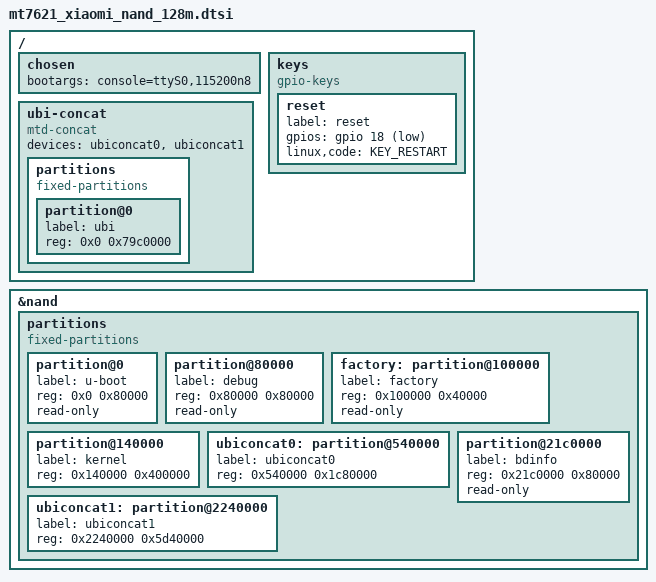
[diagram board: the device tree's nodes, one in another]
// SPDX-License-Identifier: GPL-2.0-or-later OR MIT

#include "mt7621.dtsi"

#include <dt-bindings/gpio/gpio.h>
#include <dt-bindings/input/input.h>

/ {
	chosen {
		bootargs = "console=ttyS0,115200n8";
	};

	keys: keys {
		compatible = "gpio-keys";

		reset {
			label = "reset";
			gpios = <&gpio 18 GPIO_ACTIVE_LOW>;
			linux,code = <KEY_RESTART>;
		};
	};


	ubi-concat {
		compatible = "mtd-concat";
		devices = <&ubiconcat0 &ubiconcat1>;

		partitions {
			compatible = "fixed-partitions";
			#address-cells = <1>;
			#size-cells = <1>;

			partition@0 {
				label = "ubi";
				reg = <0x0 0x79c0000>;
			};
		};
	};
};

&nand {
	status = "okay";

	partitions {
		compatible = "fixed-partitions";
		#address-cells = <1>;
		#size-cells = <1>;

		partition@0 {
			label = "u-boot";
			reg = <0x0 0x80000>;
			read-only;
		};

		partition@80000 {
			label = "debug";
			reg = <0x80000 0x80000>;
			read-only;
		};

		factory: partition@100000 {
			label = "factory";
			reg = <0x100000 0x40000>;
			read-only;
		};

		partition@140000 {
			label = "kernel";
			reg = <0x140000 0x400000>;
		};

		ubiconcat0: partition@540000 {
			label = "ubiconcat0";
			reg = <0x540000 0x1c80000>;
		};

		partition@21c0000 {
			label = "bdinfo";
			reg = <0x21c0000 0x80000>;
			read-only;
		};

		ubiconcat1: partition@2240000 {
			label = "ubiconcat1";
			reg = <0x2240000 0x5d40000>;
		};
	};
};
